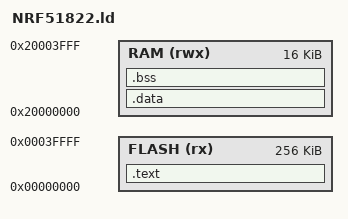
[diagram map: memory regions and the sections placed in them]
/*
 * NRF51822.ld
 *
 * This file is part of the Phos operating system for microcontrollers
 * Copyright (c) 2018 J. M. Spivey
 * All rights reserved
 *
 * Redistribution and use in source and binary forms, with or without
 * modification, are permitted provided that the following conditions are met:
 *
 * 1. Redistributions of source code must retain the above copyright notice,
 *    this list of conditions and the following disclaimer.
 * 2. Redistributions in binary form must reproduce the above copyright notice,
 *    this list of conditions and the following disclaimer in the documentation
 *    and/or other materials provided with the distribution.
 * 3. The name of the author may not be used to endorse or promote products
 *    derived from this software without specific prior written permission.
 *
 * THIS SOFTWARE IS PROVIDED BY THE AUTHOR ``AS IS'' AND ANY EXPRESS OR
 * IMPLIED WARRANTIES, INCLUDING, BUT NOT LIMITED TO, THE IMPLIED WARRANTIES
 * OF MERCHANTABILITY AND FITNESS FOR A PARTICULAR PURPOSE ARE DISCLAIMED.
 * IN NO EVENT SHALL THE AUTHOR BE LIABLE FOR ANY DIRECT, INDIRECT, INCIDENTAL,
 * SPECIAL, EXEMPLARY, OR CONSEQUENTIAL DAMAGES (INCLUDING, BUT NOT LIMITED TO,
 * PROCUREMENT OF SUBSTITUTE GOODS OR SERVICES; LOSS OF USE, DATA, OR PROFITS;
 * OR BUSINESS INTERRUPTION) HOWEVER CAUSED AND ON ANY THEORY OF LIABILITY,
 * WHETHER IN CONTRACT, STRICT LIABILITY, OR TORT (INCLUDING NEGLIGENCE OR
 * OTHERWISE) ARISING IN ANY WAY OUT OF THE USE OF THIS SOFTWARE, EVEN IF
 * ADVISED OF THE POSSIBILITY OF SUCH DAMAGE.
 */

MEMORY {
    FLASH (rx) : ORIGIN = 0x00000000, LENGTH = 0x40000
    RAM (rwx) :  ORIGIN = 0x20000000, LENGTH = 0x4000
}

OUTPUT_FORMAT ("elf32-littlearm")

SECTIONS {
    .text : {
        KEEP(*(.vectors))
        *(.text*)
        *(.rodata*)
        . = ALIGN(4);
    } > FLASH

    __etext = .;

    .data : AT (__etext) {
        __data_start = .;
        *(.data*)
        . = ALIGN(4);
        __data_end = .;
    } > RAM

    .bss : {
        __bss_start = .;
        *(.bss*)
        *(COMMON)
        . = ALIGN(4);
        __bss_end = .;
        __end = .;
    } > RAM

    /* Set stack top to end of RAM, and move stack limit down by
       size of stack */
    __stack = ORIGIN(RAM) + LENGTH(RAM);
    __stack_limit = __stack - 2048;

    /* Check if data + stack exceeds RAM limit */
    ASSERT(__stack_limit >= __end, "region RAM overlaps with stack")
}
